# STM32G0C1VET6 register map
File version: 1.0
Registers are 32-bit, access not given, reset 0x0 unless marked. A register's access mark holds for its fields unless they carry their own. Offsets are from the block's base; [hi:lo] are bit positions.

## DAC1
Base 0x40007400
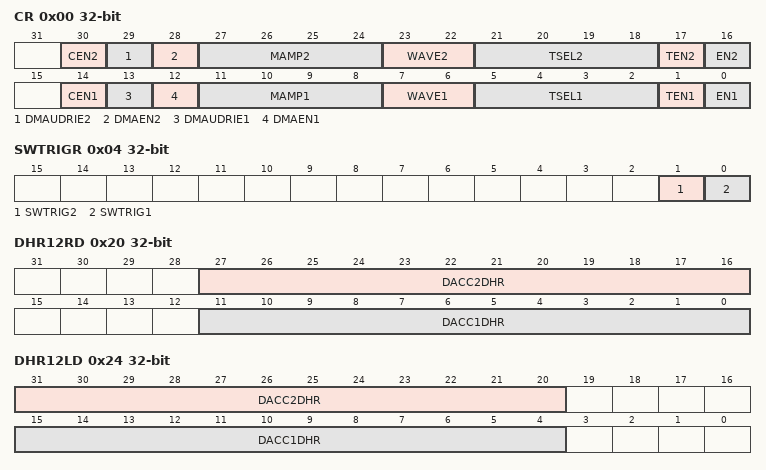
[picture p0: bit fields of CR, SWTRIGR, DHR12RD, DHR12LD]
0x00 CR
  [30] CEN2, [29] DMAUDRIE2, [28] DMAEN2, [27:24] MAMP2, [23:22] WAVE2, [21:18] TSEL2, [17] TEN2, [16] EN2, [14] CEN1, [13] DMAUDRIE1, [12] DMAEN1, [11:8] MAMP1, [7:6] WAVE1, [5:2] TSEL1, [1] TEN1, [0] EN1
0x04 SWTRIGR
  [1] SWTRIG2, [0] SWTRIG1
0x08 DHR12R1
  [11:0] DACC1DHR
0x0C DHR12L1
  [15:4] DACC1DHR
0x10 DHR8R1
  [7:0] DACC1DHR
0x14 DHR12R2
  [11:0] DACC2DHR
0x18 DHR12L2
  [15:4] DACC2DHR
0x1C DHR8R2
  [7:0] DACC2DHR
0x20 DHR12RD
  [27:16] DACC2DHR, [11:0] DACC1DHR
0x24 DHR12LD
  [31:20] DACC2DHR, [15:4] DACC1DHR
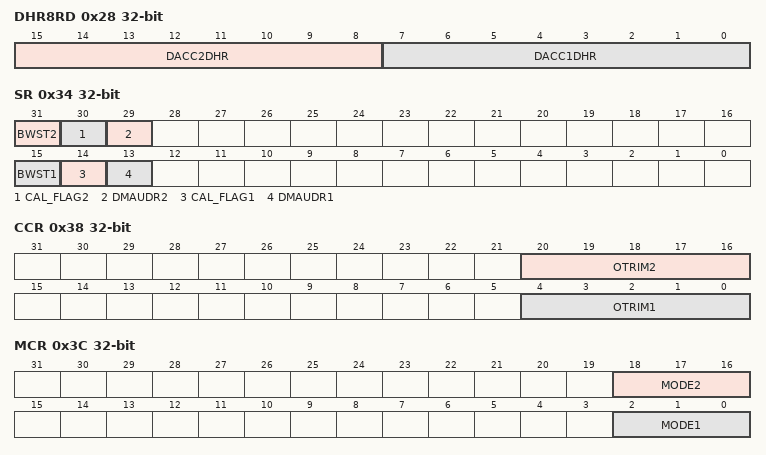
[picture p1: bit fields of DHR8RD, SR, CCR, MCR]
0x28 DHR8RD
  [15:8] DACC2DHR, [7:0] DACC1DHR
0x2C DOR1
  [11:0] DACC1DOR
0x30 DOR2
  [11:0] DACC2DOR
0x34 SR
  [31] BWST2, [30] CAL_FLAG2, [29] DMAUDR2, [15] BWST1, [14] CAL_FLAG1, [13] DMAUDR1
0x38 CCR
  [20:16] OTRIM2, [4:0] OTRIM1
0x3C MCR
  [18:16] MODE2, [2:0] MODE1
0x40 SHSR1
  [9:0] TSAMPLE1
0x44 SHSR2
  [9:0] TSAMPLE2
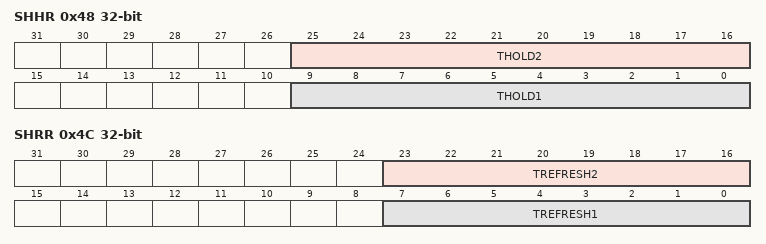
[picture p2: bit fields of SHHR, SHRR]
0x48 SHHR
  [25:16] THOLD2, [9:0] THOLD1
0x4C SHRR
  [23:16] TREFRESH2, [7:0] TREFRESH1

## CEC
Base 0x40007800
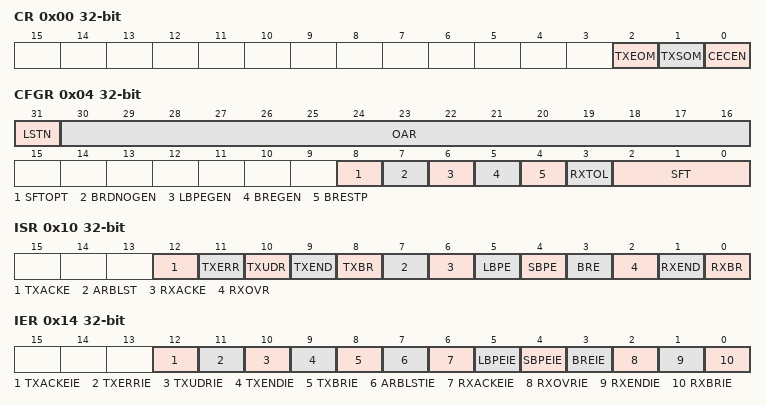
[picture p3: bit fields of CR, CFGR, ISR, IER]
0x00 CR
  [2] TXEOM, [1] TXSOM, [0] CECEN
0x04 CFGR
  [31] LSTN, [30:16] OAR, [8] SFTOPT, [7] BRDNOGEN, [6] LBPEGEN, [5] BREGEN, [4] BRESTP, [3] RXTOL, [2:0] SFT
0x08 TXDR
  [7:0] TXD
0x0C RXDR
  [7:0] RXD
0x10 ISR
  [12] TXACKE, [11] TXERR, [10] TXUDR, [9] TXEND, [8] TXBR, [7] ARBLST, [6] RXACKE, [5] LBPE, [4] SBPE, [3] BRE, [2] RXOVR, [1] RXEND, [0] RXBR
0x14 IER
  [12] TXACKEIE, [11] TXERRIE, [10] TXUDRIE, [9] TXENDIE, [8] TXBRIE, [7] ARBLSTIE, [6] RXACKEIE, [5] LBPEIE, [4] SBPEIE, [3] BREIE, [2] RXOVRIE, [1] RXENDIE, [0] RXBRIE

## LPTIM1
Base 0x40007C00
Same registers: LPTIM2 0x40009400
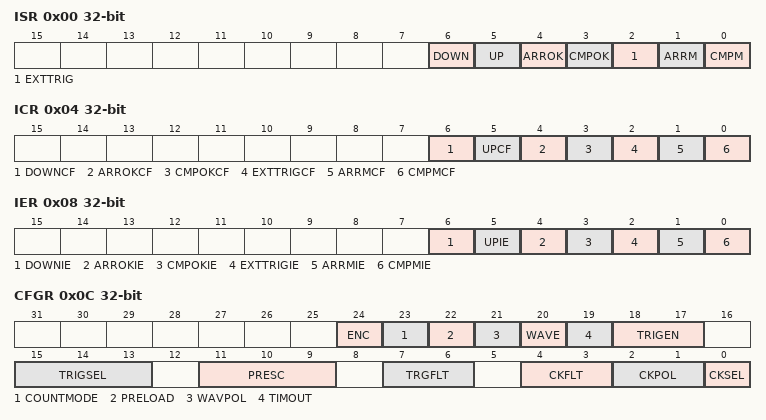
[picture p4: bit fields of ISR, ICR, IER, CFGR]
0x00 ISR
  [6] DOWN, [5] UP, [4] ARROK, [3] CMPOK, [2] EXTTRIG, [1] ARRM, [0] CMPM
0x04 ICR
  [6] DOWNCF, [5] UPCF, [4] ARROKCF, [3] CMPOKCF, [2] EXTTRIGCF, [1] ARRMCF, [0] CMPMCF
0x08 IER
  [6] DOWNIE, [5] UPIE, [4] ARROKIE, [3] CMPOKIE, [2] EXTTRIGIE, [1] ARRMIE, [0] CMPMIE
0x0C CFGR
  [24] ENC, [23] COUNTMODE, [22] PRELOAD, [21] WAVPOL, [20] WAVE, [19] TIMOUT, [18:17] TRIGEN, [15:13] TRIGSEL, [11:9] PRESC, [7:6] TRGFLT, [4:3] CKFLT, [2:1] CKPOL, [0] CKSEL
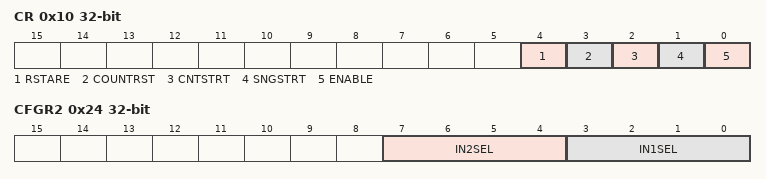
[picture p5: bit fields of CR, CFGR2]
0x10 CR
  [4] RSTARE, [3] COUNTRST, [2] CNTSTRT, [1] SNGSTRT, [0] ENABLE
0x14 CMP
  [15:0] CMP
0x18 ARR
  [15:0] ARR
0x1C CNT
  [15:0] CNT
0x24 CFGR2
  [7:4] IN2SEL, [3:0] IN1SEL

## USB_DRD_PMA_BUFF
Base 0x40009800
0x00 TXBD
0x04 RXBD

## UCPD1
Base 0x4000A000
Same registers: UCPD2 0x4000A400
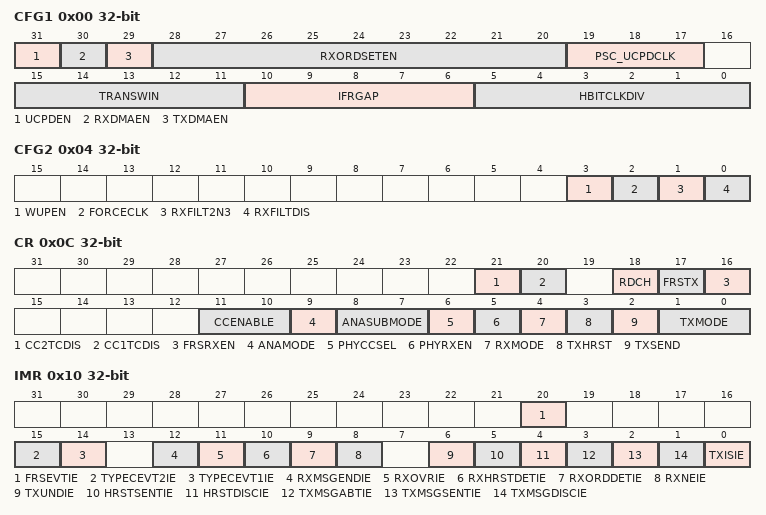
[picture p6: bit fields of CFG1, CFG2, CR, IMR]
0x00 CFG1
  [31] UCPDEN, [30] RXDMAEN, [29] TXDMAEN, [28:20] RXORDSETEN, [19:17] PSC_UCPDCLK, [15:11] TRANSWIN, [10:6] IFRGAP, [5:0] HBITCLKDIV
0x04 CFG2
  [3] WUPEN, [2] FORCECLK, [1] RXFILT2N3, [0] RXFILTDIS
0x0C CR
  [21] CC2TCDIS, [20] CC1TCDIS, [18] RDCH, [17] FRSTX, [16] FRSRXEN, [11:10] CCENABLE, [9] ANAMODE, [8:7] ANASUBMODE, [6] PHYCCSEL, [5] PHYRXEN, [4] RXMODE, [3] TXHRST, [2] TXSEND, [1:0] TXMODE
0x10 IMR
  [20] FRSEVTIE, [15] TYPECEVT2IE, [14] TYPECEVT1IE, [12] RXMSGENDIE, [11] RXOVRIE, [10] RXHRSTDETIE, [9] RXORDDETIE, [8] RXNEIE, [6] TXUNDIE, [5] HRSTSENTIE, [4] HRSTDISCIE, [3] TXMSGABTIE, [2] TXMSGSENTIE, [1] TXMSGDISCIE, [0] TXISIE
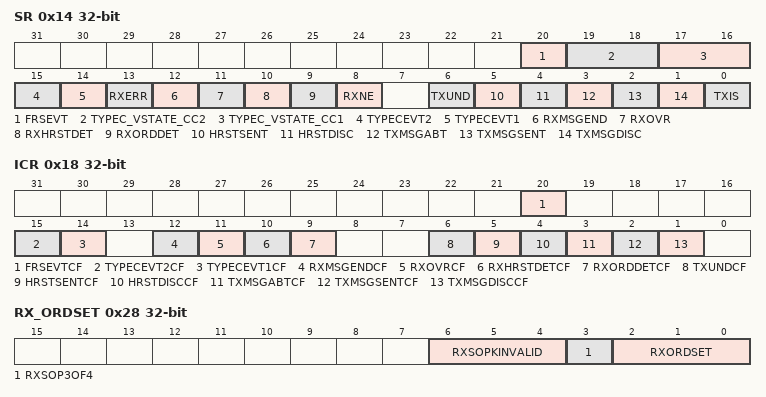
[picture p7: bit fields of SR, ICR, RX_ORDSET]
0x14 SR
  [20] FRSEVT, [19:18] TYPEC_VSTATE_CC2, [17:16] TYPEC_VSTATE_CC1, [15] TYPECEVT2, [14] TYPECEVT1, [13] RXERR, [12] RXMSGEND, [11] RXOVR, [10] RXHRSTDET, [9] RXORDDET, [8] RXNE, [6] TXUND, [5] HRSTSENT, [4] HRSTDISC, [3] TXMSGABT, [2] TXMSGSENT, [1] TXMSGDISC, [0] TXIS
0x18 ICR
  [20] FRSEVTCF, [15] TYPECEVT2CF, [14] TYPECEVT1CF, [12] RXMSGENDCF, [11] RXOVRCF, [10] RXHRSTDETCF, [9] RXORDDETCF, [6] TXUNDCF, [5] HRSTSENTCF, [4] HRSTDISCCF, [3] TXMSGABTCF, [2] TXMSGSENTCF, [1] TXMSGDISCCF
0x1C TX_ORDSET
  [19:0] TXORDSET
0x20 TX_PAYSZ
  [9:0] TXPAYSZ
0x24 TXDR
  [7:0] TXDATA
0x28 RX_ORDSET
  [6:4] RXSOPKINVALID, [3] RXSOP3OF4, [2:0] RXORDSET
0x2C RX_PAYSZ
  [9:0] RXPAYSZ
0x30 RXDR
  [7:0] RXDATA
0x34 RX_ORDEXT1
  [19:0] RXSOPX1
0x38 RX_ORDEXT2
  [19:0] RXSOPX2
